# DSP_ICFG register map
Vendor: Texas Instruments
Peripheral module from a debugger description file (folder awr2544).
Registers are 32-bit, access not given, no defined reset value unless marked. A register's access mark holds for its fields unless they carry their own. Offsets are as the file gives them; lines under a group give offsets from that group; [hi:lo] are bit positions; {n}, {i} and the like mark numbered series; 'fields as' and 'values as' point back to an identical list; <NAME> marks a mode.

## DSP_ICFG
0x00 EVTFLAG0_{i} ro (i=0..3) — Event flags
  [31:0] EF
{0x4+4i} EVTFLAG1_{i} ro (i=0..3) — Event flags
  [31:0] EF
{0x8+4i} EVTFLAG2_{i} ro (i=0..3) — Event flags
  [31:0] EF
{0xC+4i} EVTFLAG3_{i} ro (i=0..3) — Event flags
  [31:0] EF
{0x20+4i} EVTSET{i}_0 wo (i=0..3) — Event set command register
  [31:0] ES — Event set command
{0x24+4i} EVTSET{i}_1 wo (i=0..3) — Event set command register
  [31:0] ES — Event set command
{0x28+4i} EVTSET{i}_2 wo (i=0..3) — Event set command register
  [31:0] ES — Event set command
{0x2C+4i} EVTSET{i}_3 wo (i=0..3) — Event set command register
  [31:0] ES — Event set command
{0x40+4i} EVTCLR{i}_0 wo (i=0..3) — Event clear command register
  [31:0] EC — Event clear command
{0x44+4i} EVTCLR{i}_1 wo (i=0..3) — Event clear command register
  [31:0] EC — Event clear command
{0x48+4i} EVTCLR{i}_2 wo (i=0..3) — Event clear command register
  [31:0] EC — Event clear command
{0x4C+4i} EVTCLR{i}_3 wo (i=0..3) — Event clear command register
  [31:0] EC — Event clear command
{0x80+4i} EVTMASK{i}_0 rw (i=0..3) — Event mask register
  [31:0] EM — Event mask
{0x84+4i} EVTMASK{i}_1 rw (i=0..3) — Event mask register
  [31:0] EM — Event mask
{0x88+4i} EVTMASK{i}_2 rw (i=0..3) — Event mask register
  [31:0] EM — Event mask
{0x8C+4i} EVTMASK{i}_3 rw (i=0..3) — Event mask register
  [31:0] EM — Event mask
{0xA0+4i} MEVTFLAG{i}_0 ro (i=0..3) — Masked event flags
  [31:0] MEVTFLAG
{0xA4+4i} MEVTFLAG{i}_1 ro (i=0..3) — Masked event flags
  [31:0] MEVTFLAG
{0xA8+4i} MEVTFLAG{i}_2 ro (i=0..3) — Masked event flags
  [31:0] MEVTFLAG
{0xAC+4i} MEVTFLAG{i}_3 ro (i=0..3) — Masked event flags
  [31:0] MEVTFLAG
{0xC0+4i} EXPMASK{i}_0 rw (i=0..3) — Exception mask register
  [31:0] XM — Exception mask
{0xC4+4i} EXPMASK{i}_1 rw (i=0..3) — Exception mask register
  [31:0] XM — Exception mask
{0xC8+4i} EXPMASK{i}_2 rw (i=0..3) — Exception mask register
  [31:0] XM — Exception mask
{0xCC+4i} EXPMASK{i}_3 rw (i=0..3) — Exception mask register
  [31:0] XM — Exception mask
{0xE0+4i} MEXPFLAG{i}_0 ro (i=0..3) — Masked exception flags
  [31:0] MEXPFLAG
{0xE4+4i} MEXPFLAG{i}_1 ro (i=0..3) — Masked exception flags
  [31:0] MEXPFLAG
{0xE8+4i} MEXPFLAG{i}_2 ro (i=0..3) — Masked exception flags
  [31:0] MEXPFLAG
{0xEC+4i} MEXPFLAG{i}_3 ro (i=0..3) — Masked exception flags
  [31:0] MEXPFLAG
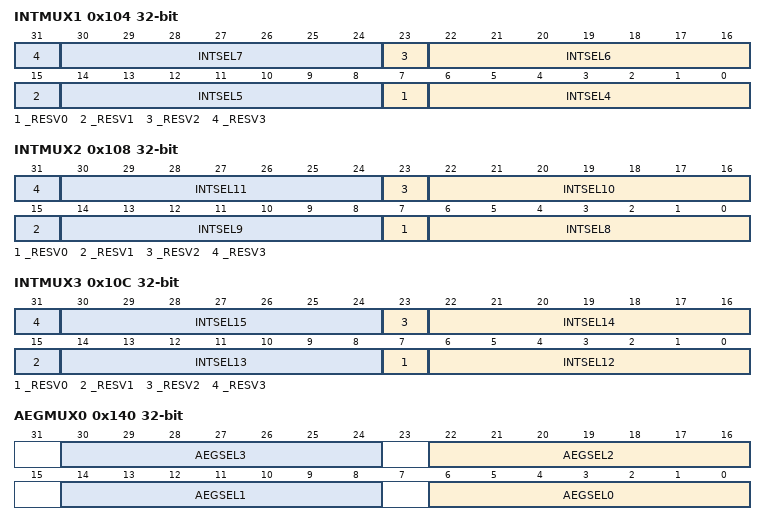
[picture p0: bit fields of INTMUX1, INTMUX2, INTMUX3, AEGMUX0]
0x104 INTMUX1 — Interrupt Mux Register
  [8n+7] _RESV{n} (n=0..3) — Always read as 0. Writes have no affect.
  [8n-26:8n-32] INTSEL{n} rw (n=4..7) — Interrupt selector {n}
0x108 INTMUX2 — Interrupt Mux Register
  [8n+7] _RESV{n} (n=0..3) — Always read as 0. Writes have no affect.
  [8n-58:8n-64] INTSEL{n} rw (n=8..11) — Interrupt selector {n}
0x10C INTMUX3 — Interrupt Mux Register
  [8n+7] _RESV{n} (n=0..3) — Always read as 0. Writes have no affect.
  [8n-90:8n-96] INTSEL{n} rw (n=12..15) — Interrupt selector {n}
0x140 AEGMUX0 rw — AEG Event Mux Register
  [8n+6:8n] AEGSEL{n} (n=0..3) — AEG event selector {n}
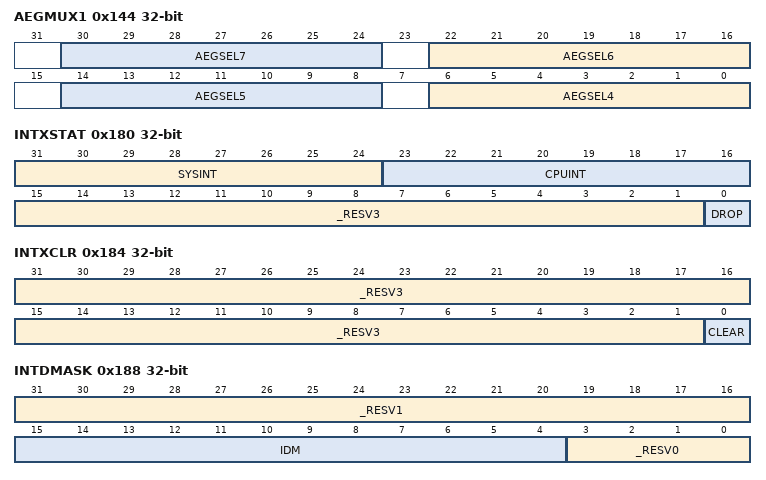
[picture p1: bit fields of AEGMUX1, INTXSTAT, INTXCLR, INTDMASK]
0x144 AEGMUX1 rw — AEG Event Mux Register
  [8n-26:8n-32] AEGSEL{n} (n=4..7) — AEG event selector {n}
0x180 INTXSTAT — Interrupt Exception Status Register
  [31:24] SYSINT ro — System event number
  [23:16] CPUINT ro — CPU interrupt number
  [15:1] _RESV3 — Always read as 0. Writes have no affect.
  [0] DROP ro — Dropped event flag
0x184 INTXCLR — Interrupt Exception Clear Register
  [31:1] _RESV3 — Always read as 0. Writes have no affect.
  [0] CLEAR wo — Clear interrupt exception status
0x188 INTDMASK — Dropped Interrupt Mask Register
  [31:16] _RESV1 — Always read as 0. Writes have no affect.
  [15:4] IDM rw — Interrupt drop mask
  [3:0] _RESV0 — Always read as 0. Writes have no affect.
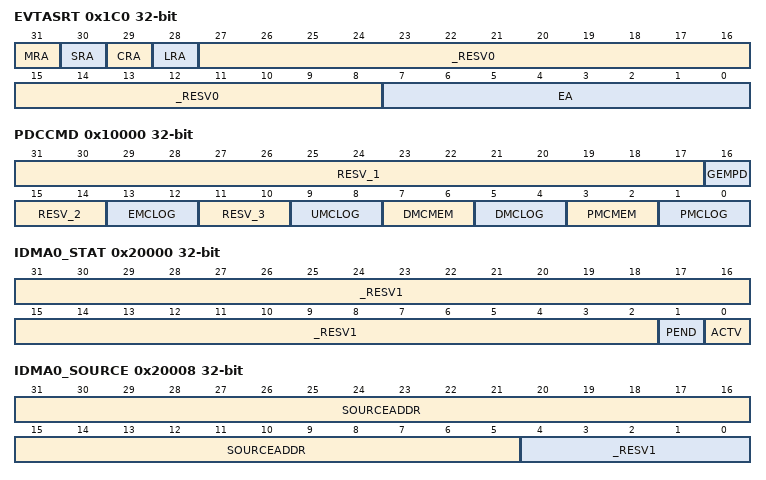
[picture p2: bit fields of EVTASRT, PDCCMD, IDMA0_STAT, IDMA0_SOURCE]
0x1C0 EVTASRT — Event Assert Register
  [31] MRA wo — Maximal Reset Request Assert
  [30] SRA wo — System Reset Request Assert
  [29] CRA wo — Chip Reset Request Assert
  [28] LRA wo — Local Reset Request Assert
  [27:8] _RESV0 — Always read as 0. Writes have no affect.
  [7:0] EA wo — Event Assert
0x10000 PDCCMD
  [31:17] RESV_1 — Always read as 0. Writes have no affect.
  [16] GEMPD rw — Enable power-down during IDLE
  [15:14] RESV_2 — Always read as 0. Writes have no affect.
  [13:12] EMCLOG rw — EMC SRAM Sleep Mode
  [11:10] RESV_3 — Always read as 0. Writes have no affect.
  [9:8] UMCLOG rw — UMC SRAM Sleep Mode
  [7:6] DMCMEM rw — DMC Logic Clock Gating
  [5:4] DMCLOG rw — DMC SRAM Sleep Mode
  [3:2] PMCMEM rw — PMC Logic Clock Gating
  [1:0] PMCLOG rw — PMC SRAM Sleep Mode
0x12000 MM_REVID rw
0x20000 IDMA0_STAT — IDMA Channel 0 Status
  [31:2] _RESV1 — Always read as 0. Writes have no affect.
  [1] PEND ro — Command pending
  [0] ACTV ro — Command active
0x20004 IDMA0_MASK rw — IDMA Channel 0 Register Mask
0x20008 IDMA0_SOURCE — IDMA Channel 0 Source Address
  [31:5] SOURCEADDR rw — Source address
  [4:0] _RESV1 — Always read as 0. Writes have no affect.
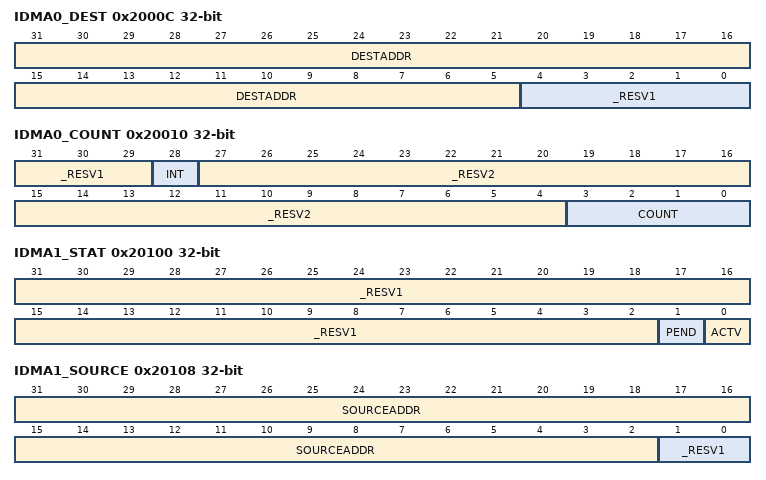
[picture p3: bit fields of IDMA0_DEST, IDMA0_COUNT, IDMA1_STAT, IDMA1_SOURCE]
0x2000C IDMA0_DEST — IDMA Channel 0 Destination Address
  [31:5] DESTADDR rw — Destination address
  [4:0] _RESV1 — Always read as 0. Writes have no affect.
0x20010 IDMA0_COUNT — IDMA Channel 0 Count
  [31:29] _RESV1 — Always read as 0. Writes have no affect.
  [28] INT rw — Interrupt enable
  [27:4] _RESV2 — Always read as 0. Writes have no affect.
  [3:0] COUNT rw — Transfer frame count
0x20100 IDMA1_STAT
  fields as IDMA0_STAT
0x20108 IDMA1_SOURCE
  [31:2] SOURCEADDR rw — Source address
  [1:0] _RESV1 — Always read as 0. Writes have no affect.
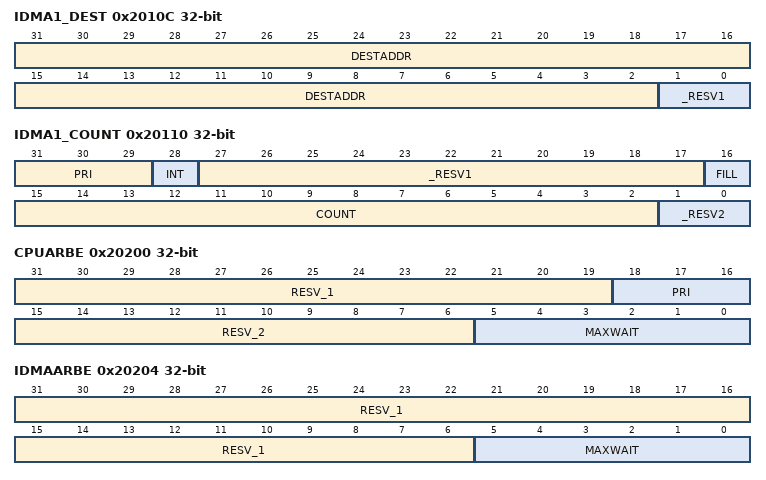
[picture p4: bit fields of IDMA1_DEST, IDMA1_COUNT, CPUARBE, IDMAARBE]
0x2010C IDMA1_DEST
  [31:2] DESTADDR rw — Destination address
  [1:0] _RESV1 — Always read as 0. Writes have no affect.
0x20110 IDMA1_COUNT
  [31:29] PRI rw — Priority
  [28] INT rw — Interrupt enable
  [27:17] _RESV1 — Always read as 0. Writes have no affect.
  [16] FILL rw — Fill/Copy Mode Select
  [15:2] COUNT rw — Transfer word count
  [1:0] _RESV2 — Always read as 0. Writes have no affect.
0x20200 CPUARBE
  [31:19] RESV_1 — Always read as 0. Writes have no affect.
  [18:16] PRI rw — Priority
  [15:6] RESV_2 — Always read as 0. Writes have no affect.
  [5:0] MAXWAIT rw — Max wait count
0x20204 IDMAARBE
  [31:6] RESV_1 — Always read as 0. Writes have no affect.
  [5:0] MAXWAIT rw — Max wait count
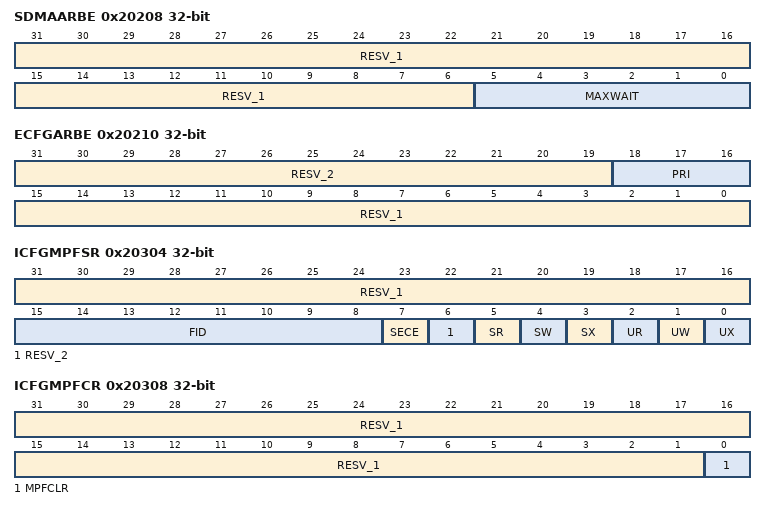
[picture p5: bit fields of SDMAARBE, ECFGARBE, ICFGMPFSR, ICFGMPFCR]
0x20208 SDMAARBE
  fields as IDMAARBE
0x20210 ECFGARBE
  [31:19] RESV_2 — Always read as 0. Writes have no affect.
  [18:16] PRI rw — Priority
  [15:0] RESV_1 — Always read as 0. Writes have no affect.
0x20300 ICFGMPFAR ro
  [31:0] ADDR
0x20304 ICFGMPFSR
  [31:16] RESV_1 — Always read as 0. Writes have no affect.
  [15:8] FID ro — PrivID of faulting requestor
  [7] SECE ro — Security Error
  [6] RESV_2 — Always read as 0. Writes have no affect.
  [5] SR ro — Fault due to Supervisor Read
  [4] SW ro — Fault due to Supervisor Write
  [3] SX ro — Fault due to Supervisor Execute
  [2] UR ro — Fault due to User Read
  [1] UW ro — Fault due to User Write
  [0] UX ro — Fault due to User Execute
0x20308 ICFGMPFCR
  [31:1] RESV_1 — Always read as 0. Writes have no affect.
  [0] MPFCLR wo
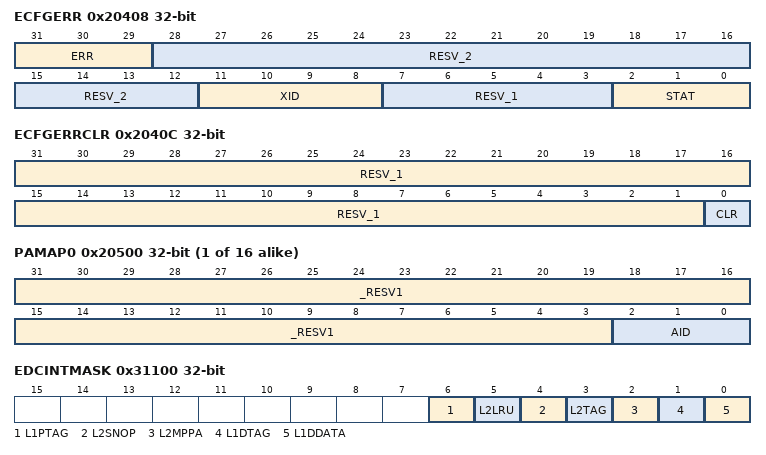
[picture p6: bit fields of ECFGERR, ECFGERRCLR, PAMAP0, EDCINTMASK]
0x20408 ECFGERR
  [31:29] ERR ro — Error
  [28:12] RESV_2 — Always read as 0. Writes have no affect.
  [11:8] XID ro
  [7:3] RESV_1 — Always read as 0. Writes have no affect.
  [2:0] STAT ro — Status
0x2040C ECFGERRCLR
  [31:1] RESV_1 — Always read as 0. Writes have no affect.
  [0] CLR ro — Error clear
{0x20500+4i} PAMAP{i} (i=0..15) — PAMAP register
  [31:3] _RESV1 — Always read as 0. Writes have no affect.
  [2:0] AID rw
0x31100 EDCINTMASK — This read write registers contains the masks for the exceptions generated by each of the EDC error detection units added in this change. Also contained in this register are the bit fields indicating which module has issued an exception. Reads of this register do not affect the mask bits but do clear the exception bits.
  [6] L1PTAG — L1PTAG Exception Enable: 1 enables the propagation of the exceptions generated from the error detector. Write 0 to disable exceptions.
  [5] L2LRU — L2LRU Exception Enable: 1 enables the propagation of the exceptions generated from the error detector. Write 0 to disable exceptions.
  [4] L2SNOP — L2SNOP Exception Enable: 1 enables the propagation of the exceptions generated from the error detector. Write 0 to disable exceptions.
  [3] L2TAG — L2TAG Exception Enable: 1 enables the propagation of the exceptions generated from the error detector. Write 0 to disable exceptions.
  [2] L2MPPA — L2DMPPA Exception Enable: 1 enables the propagation of the exceptions generated from the error detector. Write 0 to disable exceptions.
  [1] L1DTAG — L1DTAG Exception Enable: 1 enables the propagation of the exceptions generated from the error detector. Write 0 to disable exceptions.
  [0] L1DDATA — L1DDATA Exception Enable: 1 enables the propagation of the exceptions generated from the error detector. Write 0 to disable exceptions.
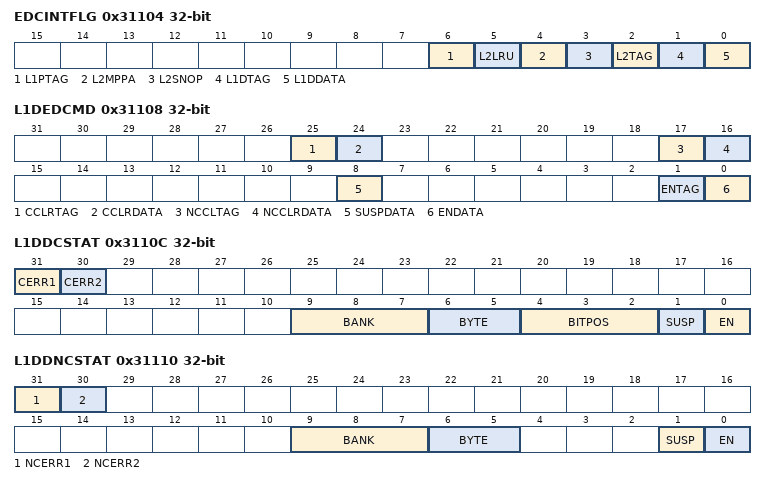
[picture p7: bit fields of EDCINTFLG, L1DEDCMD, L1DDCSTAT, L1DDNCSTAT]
0x31104 EDCINTFLG — This register loads the interrupt flags upon issue by the EDC detection module. These flags are loaded independently of any other flags. Upon a read operation all flags are cleared.
  [6] L1PTAG — L1P TAG Exception: 1 indicates that an exception has been issued from this error detector. Read of register clears bit.
  [5] L2LRU — L2 LRU Exception: 1 indicates that an exception has been issued from this error detector. Read of register clears bit.
  [4] L2MPPA — L2 MPPA Exception: 1 indicates that an exception has been issued from this error detector. Read of register clears bit.
  [3] L2SNOP — L2 SNOP Exception: 1 indicates that an exception has been issued from this error detector. Read of register clears bit.
  [2] L2TAG — L2TAG Exception: 1 indicates that an exception has been issued from this error detector. Read of register clears bit.
  [1] L1DTAG — L1DTAG Exception: 1 indicates that an exception has been issued from this error detector. Read of register clears bit.
  [0] L1DDATA — L1DDATA Exception: 1 indicates that an exception has been issued from this error detector. Read of register clears bit.
0x31108 L1DEDCMD — This write only register provides control for enabling and disabling the ECC logic ofr the DMC. This register controls the parameters which are accumulated for the Data and Tag RAMs in the DMC. Enabling the ECC allows the counting of recoverable and non-recoverable errors as well as registering the requestor and the address and cache states for any ECC errors which are reported.
  [25] CCLRTAG rw — Correctable Error Clear: Writing 1 clears the correctable error count in the DMCEDPECNT register This is a one-shot register, and is cleared immediately.
  [24] CCLRDATA rw — Non-Correctable Error Clear: Writeing 1 clears the noncorrectable error count in the DMCEDPECNT register. This is a one-shot register and is cleared immediately.
  [17] NCCLTAG rw — Correctable Error Clear: Writing 1 clears the correctable error count in the DMCEDPECNT register This is a one-shot register, and is cleared immediately.
  [16] NCCLRDATA rw — Non-Correctable Error Clear: Writeing 1 clears the noncorrectable error count in the DMCEDPECNT register. This is a one-shot register and is cleared immediately.
  [8] SUSPDATA rw — Suspend TAG: Write 1 to prevent hamming codes from being written into memory but allows data to be written.
  [1] ENTAG rw — Enable Data: Initialized to the active state (1), to disable EDC on Data write 0
  [0] ENDATA rw — Enable TAG: Initialized to the active state (1), to disable EDC on TAG write 0.
0x3110C L1DDCSTAT — This read only regsister contains the current error data for Correctable ECC errors. The register provides information on whether the error was correctable or non-correctable, the requestor, and what position the error was located. . The error information is written upon the occurrence of the first ECC error encountered. CERR1 is set, and the values are retained. If any additional ECC errors occur, this is indicated by setting CERR2.
  [31] CERR1 — Correctable Error 1: Indicates that one correctable error has occurred and that they BANK, BYTE and BITPOS values are valid. Cleared upon writing a 1 to L1DEDCMD.CCLRDATA
  [30] CERR2 — Correctable Error 2: Indicates that a subsequent correctable error has occurred ,BANK, BYTE and BITPOS values are valid but apply to the error reported in CERR1. Cleared upon writing a 1 to L1DEDCMD.CCLRDATA
  [9:7] BANK — BANK Number: This value indicates the bank number of the error indicated when CERR1 is 1. This value is the lowest numbered bank if multiple banks error simultaneously. This value is set upon the first error occurring and is cleared by writing a 1 to L1DEDCMD.CCLRDATA.
  [6:5] BYTE — Byte Number: This value indicates the byte number ot the error indicated when CERR1 is 1. This value is the lowest numbered byte if multiple bytes error simultaneously in the same bank.This value is set upon the first error occurring and is cleared by writing a 1 to L1DEDCMD.CCLRDATA.
  [4:2] BITPOS — Bit Position: This value indicates the bit position of the error indicated when CERR1 is 1. This value is the specific single error bits from the byte indicated by BYTE and the bank indicated by BANK. This value is set upon the first error occurring and is cleared by writing a 1 to L1DEDCMD.CCLRDATA.
  [1] SUSP — Suspend: EDC logic is in suspend mode, this value is representative of the state of the last write to L1DEDCMD.SUSPDATA.
  [0] EN — EDC Enable: Indicates EDC logic is enabled, this value is representative of the state of the last write to L1DEDCMD.ENDATA.
0x31110 L1DDNCSTAT — This read only register contains the current error data for Correctable ECC errors. The register provides information on whether the error was correctable or non-correctable, the requestor, and what position the error was located. This register is similar to Error! Not a valid bookmark self-reference. with the exception of the bit position register fields, with two bit errors it is not possible to provide the locations. . The error information is written upon the occurrence of the first ECC error encountered. CERR1 is set, and the values are retained. If any additional ECC errors occur, this is indicated by setting CERR2. Note: Non-correctable errors do not mean two bits in the 256 bit data word, but two bits+ of error in a single byte. The EDC is capable of correcting up to 8 bits in a single word if there are only single bit errors in each byte.
  [31] NCERR1 — Non-Correctable Error 1: Indicates that one correctable error has occurred and that they BANK, BYTE and BITPOS values are valid. Cleared upon writing a 1 to L1DEDCMD.NCCLRDATA
  [30] NCERR2 — Non-Correctable Error 2: Indicates that a subsequent correctable error has occurred ,BANK, BYTE and BITPOS values are valid but apply to the error reported in CERR1. Cleared upon writing a 1 to L1DEDCMD.NCCLRDATA
  [9:7] BANK — BANK Number: This value indicates the bank number of the error indicated when NCERR1 is 1. This value is the lowest numbered bank if multiple banks error simultaneously. This value is set upon the first error occurring and is cleared by writing a 1 to L1DEDCMD.NCCLRDATA.
  [6:5] BYTE — Byte Number: This value indicates the byte number ot the error indicated when NCERR1 is 1. This value is the lowest numbered byte if multiple bytes error simultaneously in the same bank.This value is set upon the first error occurring and is cleared by writing a 1 to L1DEDCMD.NCCLRDATA.
  [1] SUSP — Suspend: EDC logic is in suspend mode, this value is representative of the state of the last write to L1DEDCMD.SUSPDATA
  [0] EN — EDC Enable: Indicates EDC logic is enabled, this value is representative of the state of the last write to L1DEDCMD.ENDATA.
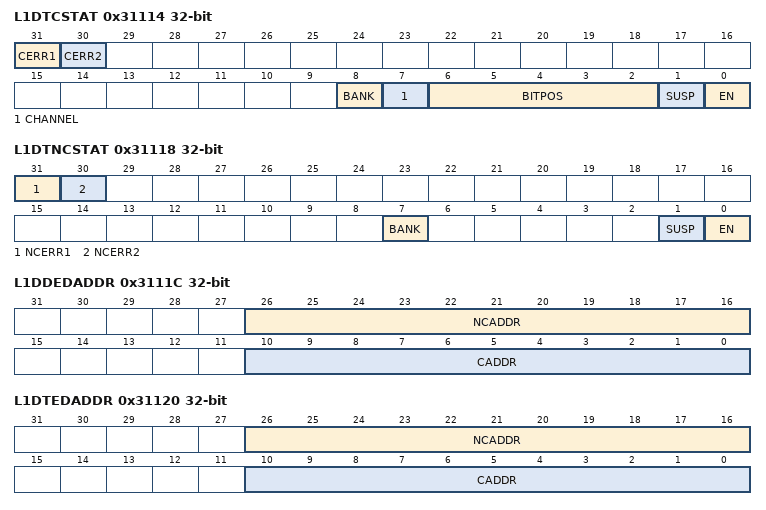
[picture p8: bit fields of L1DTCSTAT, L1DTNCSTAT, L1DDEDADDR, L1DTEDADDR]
0x31114 L1DTCSTAT — This read only regsister contains the current error data for Correctable ECC errors. The register provides information on whether the error was correctable or non-correctable, the requestor, and what position the error was located. The error information is written upon the occurrence of the first ECC error encountered. CERR1 is set, and the values are retained. If any additional ECC errors occur, this is indicated by setting CERR2.
  [31] CERR1 — Correctable Error 1: Indicates that one correctable error has occurred and that they BANK and BITPOS values are valid. Cleared upon writing a 1 to L1DEDCMD.CCLRDTAG
  [30] CERR2 — Correctable Error 2: Indicates that a subsequent correctable error has occurred ,BANK and BITPOS values are valid but apply to the error reported in CERR1. Cleared upon writing a 1 to L1DEDCMD.CCLRTAG
  [8] BANK ro — Bank: Value indicates which bank the correctable error occurred in.
  [7] CHANNEL — Channel: Access to the banks of the L1D TAG memory are split into channels: 1 = [53:43],[31:16] 2 = [42:32],[15:0] Bit Position is an index in the respective channels, this will yield the error bit position.
  [6:2] BITPOS ro — Bit Position: This value indicates the bit position of the error indicated when CERR1 is 1. This value is the specific single error bits from the byte indicated by BYTE and the bank indicated by BANK. This value is set upon the first error occurring Cleared upon writing a 1 to L1DEDCMD.CCLRTAG
  [1] SUSP — Suspend: EDC logic is in suspend mode, this value is representative of the state of the last write to L1DEDCMD.SUSPDATA
  [0] EN — EDC Enable: Indicates EDC logic is enabled, this value is representative of the state of the last write to L1DEDCMD.ENDATA.
0x31118 L1DTNCSTAT — L1D Error Detect TAG Non-Correctable Status Register
  [31] NCERR1 — Non-Correctable Error 1: Indicates that one correctable error has occurred and that they BANK, BYTE and BITPOS values are valid. Cleared upon writing a 1 to L1DEDCMD.NCCLRTAG
  [30] NCERR2 — Non-Correctable Error 2: Indicates that a subsequent correctable error has occurred ,BANK, BYTE and BITPOS values are valid but apply to the error reported in CERR1. Cleared upon writing a 1 to L1DEDCMD.NCCLRTAG
  [7] BANK — BANK Number: This value indicates the bank number of the error indicated when NCERR1 is 1. This value is the lowest numbered bank if multiple banks error simultaneously. This value is set upon the first error occurring and is cleared by writing a 1 to L1DEDCMD.NCCLRDATA.
  [1] SUSP — Suspend: EDC logic is in suspend mode, this value is representative of the state of the last write to L1DEDCMD.SUSPDATA
  [0] EN — EDC Enable: Indicates EDC logic is enabled, this value is representative of the state of the last write to L1DEDCMD.ENDATA.
0x3111C L1DDEDADDR — The L1D Correctable Error Detection Address Register pair contain the additional information on correctable errors reported in the STATUS registers. The addresses for both correctable and noncorrectable errors are held in this register. The value contained in the addresss field is the lower 16 bits of the word boundary of the memory access. If the access is to 0x00F00020, the address field will read 0x0020, if the access is to 0x00F07FE0, the address field will read 0x7FE0.
  [26:16] NCADDR — Non-Correctable Address: The value in this field is qualified by L1DEDDNCSTATE.NCERR1, when that field is written to a 1, the address of the noncorrectable error is written to this register field. . Cleared upon writing a 1 to L1DEDCMD.NCCLRDATA
  [10:0] CADDR — Correctable Address: The value in this field is qualified by L1DEDDNCSTATE.CERR1, when that field is written to a 1, the address of the non-correctable error is written to this register field. . Cleared upon writing a 1 to L1DEDCMD.NCCLRDATA
0x31120 L1DTEDADDR — The L1D Correctable Error Detection Address Register pair contain the additional information on correctable errors reported in the STATUS registers. The address for both correctable and noncorrectable errors are held in this register. The value of the address is the index (or address on the RAM) of the RAM module.
  fields as L1DDEDADDR
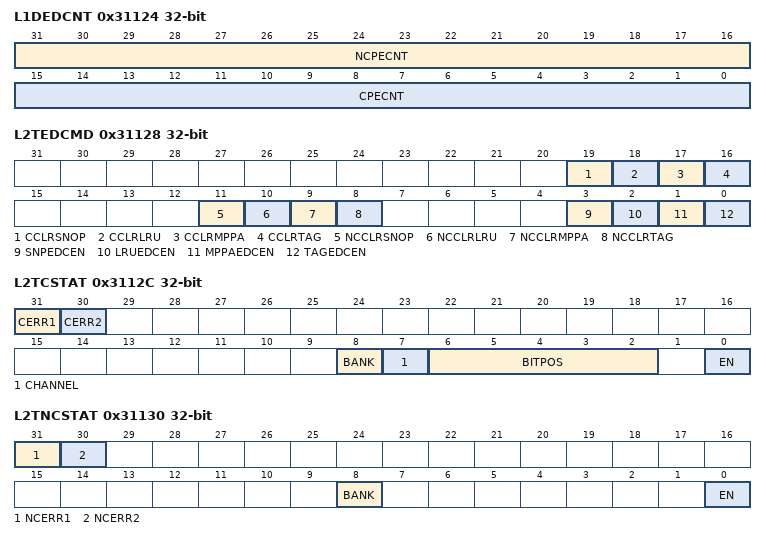
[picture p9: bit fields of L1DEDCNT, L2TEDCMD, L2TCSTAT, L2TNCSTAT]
0x31124 L1DEDCNT ro — The L1D TAG Error Detection Error Count Register.stores the error counts for correctable and noncorrectable errors which occur in the L1D Cache Memories, these counts are accumulated regardless of the exception mapping in the L1DEDCMD (0x0182_1108) interrupt enable bits. The counters capture the total number of correctable and non-correctable errors from both the DATA and TAG memories.
  [31:16] NCPECNT — Non-correctable EDC error count. Shows the number of non-correctable errors which have occurred in the DMC memories since last reset. This counter is cleared by writing a zero value to the counter.
  [15:0] CPECNT — Correctable EDC error count: Shows the number of correctable errors which have occurred in the DMC memories since last reset. This counter is cleared by writing a zero value to the counter.
0x31128 L2TEDCMD — This write only register provides control for enabling and disabling the ECC logic ofr the UMC. This register controls the parameters which are accumulated for the Data and Tag RAMs in the DMC. Enabling the ECC allows the counting of recoverable and non-recoverable errors as well as registering the requestor and the address and cache states for any ECC errors which are reported.
  [19] CCLRSNOP wo — Correctable Error Clear, SNOP: writing 1 to this register cause the corresponding counter to be cleared. The value written to this register is a one shot event.
  [18] CCLRLRU wo — Correctable Error Clear, LRU: writing 1 to this register cause the corresponding counter to be cleared. The value written to this register is a one shot event.
  [17] CCLRMPPA wo — Correctable Error Clear, MPPA: writing 1 to this register cause the corresponding counter to be cleared. The value written to this register is a one shot event.
  [16] CCLRTAG wo — Correctable Error Clear, TAG: writing 1 to this register cause the corresponding counter to be cleared. The value written to this register is a one shot event.
  [11] NCCLRSNOP wo — Non- Correctable Error Clear, SNOP: writing 1 to this register cause the corresponding counter to be cleared. The value written to this register is a one shot event.
  [10] NCCLRLRU wo — Non- Correctable Error Clear, LRU: writing 1 to this register cause the corresponding counter to be cleared. The value written to this register is a one shot event.
  [9] NCCLRMPPA wo — Non- Correctable Error Clear, MPPA: writing 1 to this register cause the corresponding counter to be cleared. The value written to this register is a one shot event.
  [8] NCCLRTAG wo — Non- Correctable Error Clear, TAG: writing 1 to this register cause the corresponding counter to be cleared. The value written to this register is a one shot event.
  [3] SNPEDCEN wo — Enable EDC: writing a 1 to this register enables EDC on the SNOOP Memory
  [2] LRUEDCEN wo — Enable EDC: writing a 1 to this register enables EDC on the LRU Memory
  [1] MPPAEDCEN wo — Enable EDC: writing a 1 to this register enables EDC on the MPPA Memory
  [0] TAGEDCEN wo — Enable EDC: writing a 1 to this register enables the EDC modules for this memory. This bit is persistent and must be actively written to 0 to disable the EDC modules.
0x3112C L2TCSTAT — This read only regsister contains the current error data for Correctable ECC errors. The register provides information on whether the error was correctable or non-correctable, the requestor, and what position the error was located.
  [31] CERR1 ro — Correctable Error 1: Indicates that one correctable error has occurred and that they BANK and BITPOS values are valid. Cleared upon writing a 1 to L2EDCMD.CCLRDTAG
  [30] CERR2 ro — Correctable Error 2: Indicates that a subsequent correctable error has occurred ,BANK and BITPOS values are valid but apply to the error reported in CERR1. Cleared upon writing a 1 to L2EDCMD.CCLRTAG
  [8] BANK ro — Bank: indicates which of the two banks (0 = BANK0, 1 = BANK1) contains the correctable error. Cleared upon writing a 1 to L2EDCMD.CCLRTAG
  [7] CHANNEL ro — Channel: Access to a bank are split, therefore an indication of channel 1 = [41:21] 2 = [20:0] Bit Position is qualified from these as displacements within the channel.
  [6:2] BITPOS ro — Bit Position: This value indicates the bit position of the error indicated when CERR1 is 1. This value is the specific single error bits from the byte indicated by BYTE and the bank indicated by BANK. This value is set upon the first error occurring Cleared upon writing a 1 to L2EDCMD.CCLRTA
  [0] EN ro — EDC Enable: Indicates EDC logic is enabled, this value is representative of the state of the last write to L1DEDCMD.ENDATA.
0x31130 L2TNCSTAT — This read only register contains the current error data for Correctable ECC errors. The register provides information on whether the error was correctable or non-correctable, the requestor, and what position the error was located.
  [31] NCERR1 ro — Non-Correctable Error 1: Indicates that one correctable error has occurred and that they BANK, BYTE and BITPOS values are valid. Cleared upon writing a 1 to L1DEDCMD.NCCLRTAG
  [30] NCERR2 ro — Non-Correctable Error 2: Indicates that a subsequent correctable error has occurred ,BANK, BYTE and BITPOS values are valid but apply to the error reported in CERR1. Cleared upon writing a 1 to L1DEDCMD.NCCLRTAG
  [8] BANK ro — Bank: indicates which of the two banks (0 = BANK0, 1 = BANK1) contains the correctable error. Cleared upon writing a 1 to L2EDCMD.CCLRTAG
  [0] EN ro — EDC Enable: Indicates EDC logic is enabled, this value is representative of the state of the last write to L1DEDCMD.ENDATA.
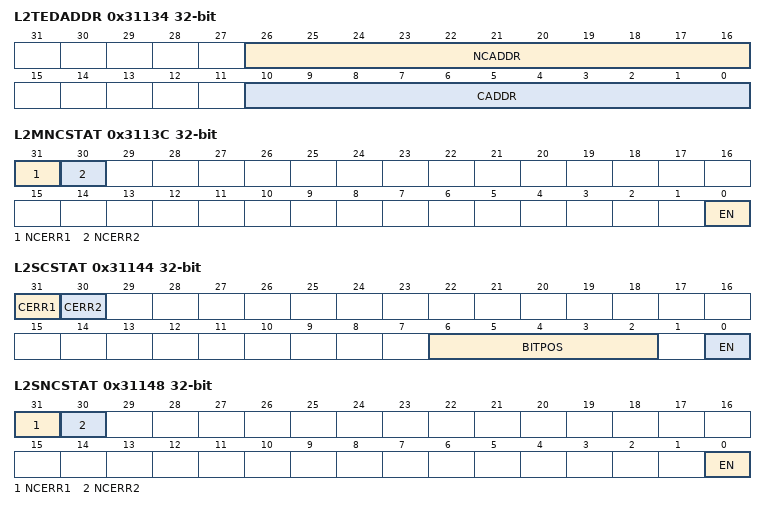
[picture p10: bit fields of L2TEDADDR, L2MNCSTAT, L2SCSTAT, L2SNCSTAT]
0x31134 L2TEDADDR — The L2Correctable Error Detection Address Register pair contain the additional information on correctable errors reported in1.3.1.12. With both exceptions activated, the TAG exception will take priority on simultaneous exceptions. The addres in these fields is the displacement into the memory as presented to the address port of the SRAM.
  [26:16] NCADDR ro — Non-Correctable Address: The value in this field is qualified by L2EDDNCSTATE.NCERR1, when that field is written to a 1, the address of the noncorrectable error is written to this register field. . Cleared upon writing a 1 to L2EDCMD.NCCLRDATA
  [10:0] CADDR ro — Correctable Address: The value in this field is qualified by L2EDDNCSTATE.CERR1, when that field is written to a 1, the address of the non-correctable error is written to this register field. . Cleared upon writing a 1 to L2EDCMD.NCCLRDATA
0x31138 L2MCSTAT — This register is non-functional as the memory is protected by parity alone and thus is non-correctable.
0x3113C L2MNCSTAT — This read only register contains the current error data for Correctable ECC errors. The register provides information on whether the error was correctable or non-correctable, the requestor, and what position the error was located.
  [31] NCERR1 ro — Non-Correctable Error 1: Indicates that one correctable error has occurred and that they BANK, BYTE and BITPOS values are valid. Cleared upon writing a 1 to L2EDCMD.NCCLRMPPA
  [30] NCERR2 ro — Non-Correctable Error 2: Indicates that a subsequent correctable error has occurred ,BANK, BYTE and BITPOS values are valid but apply to the error reported in CERR1. Cleared upon writing a 1 to L2EDCMD.NCCLRMPPA
  [0] EN ro — EDC Enable: Indicates EDC logic is enabled, this value is representative of the state of the last write to L1DEDCMD.ENEDC
0x31140 L2MEDADDR — The L2Correctable Error Detection Address Register pair contain the additional information on correctable errors reported in1.3.1.12. With both exceptions activated, the TAG exception will take priority on simultaneous exceptions.
  [26:16] NCADDR ro — Non-Correctable Address: The value in this field is qualified by L2EDSNCSTATE.NCERR1, when that field is written to a 1, the address of the non-correctable error is written to this register field. . Cleared upon writing a 1 to L2EDCMD.NCCLRMPPA
0x31144 L2SCSTAT — This read only regsister contains the current error data for Correctable ECC errors. The register provides information on whether the error was correctable or non-correctable, the requestor, and what position the error was located.
  [31] CERR1 ro — Correctable Error 1: Indicates that one correctable error has occurred and that they BANK and BITPOS values are valid. Cleared upon writing a 1 to L2EDCMD.CCLRDSNOP
  [30] CERR2 ro — Correctable Error 2: Indicates that a subsequent correctable error has occurred ,BANK and BITPOS values are valid but apply to the error reported in CERR1. Cleared upon writing a 1 to L2EDCMD.CCLRSNOP
  [6:2] BITPOS ro — Bit Position: This value indicates the bit position of the error indicated when CERR1 is 1. This value is the specific single error bits from the byte indicated by BYTE and the bank indicated by BANK. This value is set upon the first error occurring Cleared upon writing a 1 to L2EDCMD.CCLRSNOP
  [0] EN ro — EDC Enable: Indicates EDC logic is enabled, this value is representative of the state of the last write to L2EDCMD.ENEDC
0x31148 L2SNCSTAT — This read only register contains the current error data for Correctable ECC errors. The register provides information on whether the error was correctable or non-correctable, the requestor, and what position the error was located.
  [31] NCERR1 ro — Non-Correctable Error 1: Indicates that one correctable error has occurred and that they BANK, BYTE and BITPOS values are valid. Cleared upon writing a 1 to L2EDCMD.NCCLRSNOP
  [30] NCERR2 ro — Non-Correctable Error 2: Indicates that a subsequent correctable error has occurred ,BANK, BYTE and BITPOS values are valid but apply to the error reported in CERR1. Cleared upon writing a 1 to L2EDCMD.NCCLRSNOP
  [0] EN ro — EDC Enable: Indicates EDC logic is enabled, this value is representative of the state of the last write to L2EDCMD.ENEDC
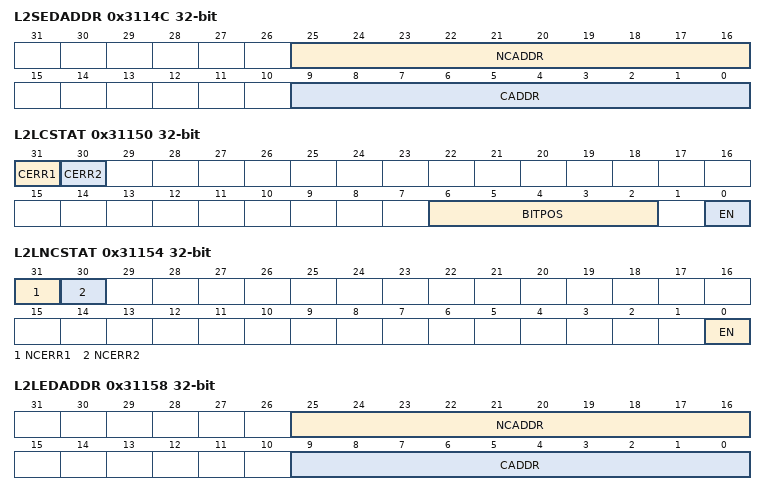
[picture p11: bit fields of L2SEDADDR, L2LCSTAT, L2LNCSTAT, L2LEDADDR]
0x3114C L2SEDADDR — The L2Correctable Error Detection Address Register pair contain the additional information on correctable errors reported in1.3.1.12. With both exceptions activated, the TAG exception will take priority on simultaneous exceptions.
  [25:16] NCADDR ro — Non-Correctable Address: The value in this field is qualified by L2EDDNCSTATE.NCERR1, when that field is written to a 1, the address of the noncorrectable error is written to this register field. . Cleared upon writing a 1 to L2EDCMD.NCCLRSNOP
  [9:0] CADDR ro — Correctable Address: The value in this field is qualified by L2EDDNCSTATE.CERR1, when that field is written to a 1, the address of the non-correctable error is written to this register field. . Cleared upon writing a 1 to L2EDCMD.NCCLRSNOP
0x31150 L2LCSTAT — This read only regsister contains the current error data for Correctable ECC errors. The register provides information on whether the error was correctable or non-correctable, the requestor, and what position the error was located.
  [31] CERR1 ro — Correctable Error 1: Indicates that one correctable error has occurred and that they BANK and BITPOS values are valid. Cleared upon writing a 1 to L2EDCMD.CCLRDLRU
  [30] CERR2 ro — Correctable Error 2: Indicates that a subsequent correctable error has occurred ,BANK and BITPOS values are valid but apply to the error reported in CERR1. Cleared upon writing a 1 to L2EDCMD.CCLRLRU
  [6:2] BITPOS ro — Bit Position: This value indicates the bit position of the error indicated when CERR1 is 1. This value is the specific single error bits from the byte indicated by BYTE and the bank indicated by BANK. This value is set upon the first error occurring Cleared upon writing a 1 to L2EDCMD.CCLRLRU
  [0] EN ro — EDC Enable: Indicates EDC logic is enabled, this value is representative of the state of the last write to L2EDCMD.ENEDC
0x31154 L2LNCSTAT
  [31] NCERR1 — Non-Correctable Error 1: Indicates that one correctable error has occurred and that they BANK, BYTE and BITPOS values are valid. Cleared upon writing a 1 to L2EDCMD.NCCLR:LRU
  [30] NCERR2 — Non-Correctable Error 2: Indicates that a subsequent correctable error has occurred ,BANK, BYTE and BITPOS values are valid but apply to the error reported in CERR1. Cleared upon writing a 1 to L2EDCMD.NCCLRLRU
  [0] EN — EDC Enable: Indicates EDC logic is enabled, this value is representative of the state of the last write to L2EDCMD.ENEDC
0x31158 L2LEDADDR ro — The L2Correctable Error Detection Address Register pair contain the additional information on correctable errors reported in1.3.1.12. With both exceptions activated, the TAG exception will take priority on simultaneous exceptions.
  [25:16] NCADDR — Non-Correctable Address: The value in this field is qualified by L2EDDNCSTATE.NCERR1, when that field is written to a 1, the address of the noncorrectable error is written to this register field. . Cleared upon writing a 1 to L2EDCMD.NCCLRLRU
  [9:0] CADDR — Correctable Address: The value in this field is qualified by L2EDDNCSTATE.CERR1, when that field is written to a 1, the address of the non-correctable error is written to this register field. . Cleared upon writing a 1 to L2EDCMD.NCCLRLRU
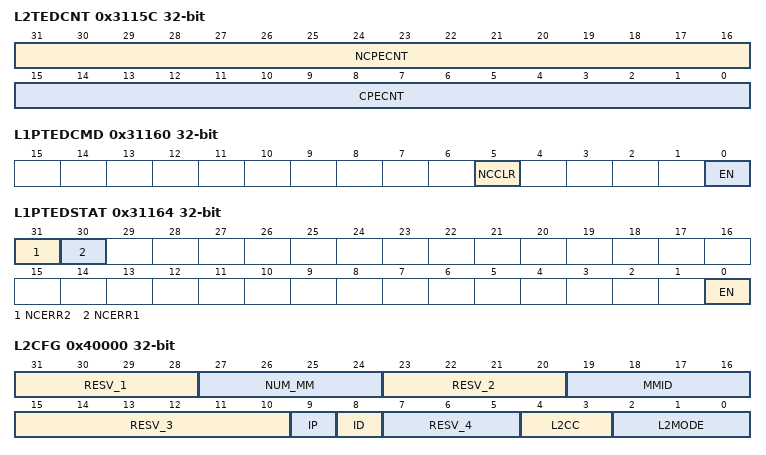
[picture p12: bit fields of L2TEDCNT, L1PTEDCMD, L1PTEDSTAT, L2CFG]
0x3115C L2TEDCNT ro — The L2 Error Detection Error Count Register.stores the error conts for correctable and non-correctable errors which occur in the L1D Data Memory, these counts are accumulated regardless of the exception mapping in the L1DEDCMD (0x0182_1108) interrupt enable bits. The counts contained in these registers are the accumulation of all L2 errors. This value saturates at an unsigned 0xFFFF.
  [31:16] NCPECNT — Non-correctable EDC error count. Shows the number of non-correctable errors which have occurred in the DMC memories since last reset. This counter is cleared by writing a zero value to the counter. CPECNT 15-0 0 Correctable EDC error count:
  [15:0] CPECNT — Correctable EDC error count: Shows the number of correctable errors which have occurred in the DMC memories since last reset. This counter is cleared by writing a zero value to the counter.
0x31160 L1PTEDCMD — This write only register provides control for enabling and disabling the Parity logic ofr the PMC. This register controls the parameters which are accumulated for the Data and Tag RAMs in the PMC. Enabling the Parity allows the counting of recoverable and non-recoverable errors as well as registering the requestor and the address and cache states for any Parity errors which are reported.
  [5] NCCLR wo — Non-Correctable Error Clear: Clears the non-correctable error count in the DMCEDPECNT register
  [0] EN wo — Enable Parity: Enables the Parity logic (parity_enable)
0x31164 L1PTEDSTAT — This read only regsister contains the current error. The register provides information on whether the error was correctable or non-correctable, the requestor, and what position the error was located.
  [31] NCERR2 ro — Non-Correctable Error: Indicates that there was a seconde non-correctable error, Also indicates the logged error is valid.
  [30] NCERR1 ro — Non-Correctable Error: Indicates the first error was noncorrectable.
  [0] EN ro — Enable: reflects the current state of the EN bit from L1PEDCMD
0x31168 L1PTEDADDR — The address error registers for correctable and non-correctable errors are identical in structure, the indication applies to the correctable and non-correctable errors, they are both covered in this section. The register provides a record of the address of the detected error and the access status or the cache.
  [26:16] NCADDR ro — Non-Correctable Address: The value in this field is qualified by L1PEDDNCSTATE.NCERR, when that field is written to a 1, the address of the non-correctable error is written to this register field. . Cleared upon writing a 1 to L1PEDCMD.NCCLRLR
0x3116C L1DTEDCNT — This read only register contains the counts of correctable and non-correctable errors which have occurred. To reset these counts write to the DMCEDCMD register in the appropriate bit.
  [31:16] NCPECNT ro — Non-correctable EDC error count. Shows the number of non-correctable errors which have occurred in the DMC memories since last reset. This counter is cleared by writing a zero value to the counter.
0x40000 L2CFG
  [31:28] RESV_1 — Always read as 0. Writes have no affect.
  [27:24] NUM_MM ro
  [23:20] RESV_2 — Always read as 0. Writes have no affect.
  [19:16] MMID ro
  [15:10] RESV_3 — Always read as 0. Writes have no affect.
  [9] IP
  [8] ID
  [7:5] RESV_4 — Always read as 0. Writes have no affect.
  [4:3] L2CC
  [2:0] L2MODE rw
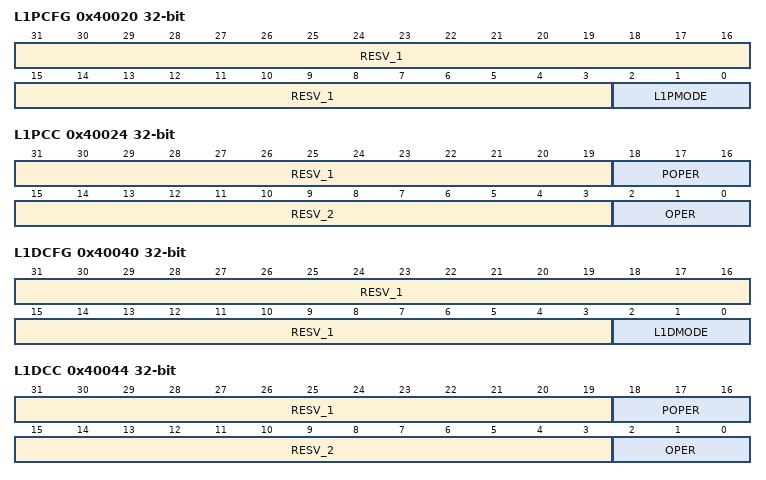
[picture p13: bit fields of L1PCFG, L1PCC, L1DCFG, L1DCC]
0x40020 L1PCFG
  [31:3] RESV_1 — Always read as 0. Writes have no affect.
  [2:0] L1PMODE rw
0x40024 L1PCC
  [31:19] RESV_1 — Always read as 0. Writes have no affect.
  [18:16] POPER ro
  [15:3] RESV_2 — Always read as 0. Writes have no affect.
  [2:0] OPER rw
0x40040 L1DCFG
  [31:3] RESV_1 — Always read as 0. Writes have no affect.
  [2:0] L1DMODE rw
0x40044 L1DCC
  fields as L1PCC
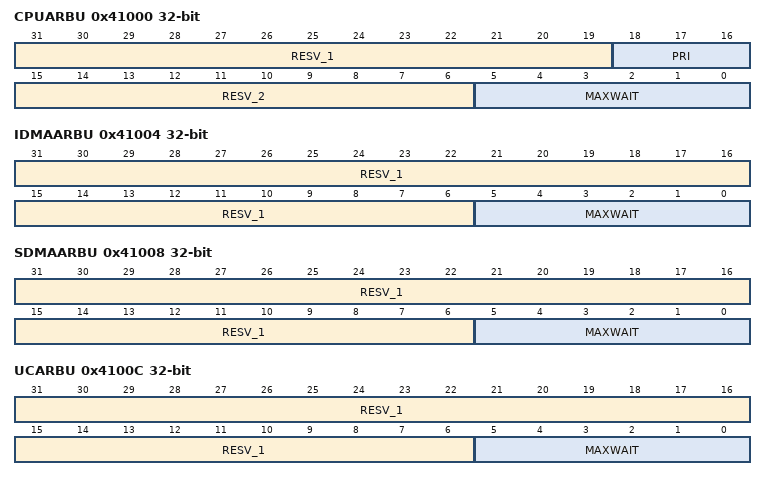
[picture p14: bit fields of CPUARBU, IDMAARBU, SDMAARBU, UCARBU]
0x41000 CPUARBU
  fields as CPUARBE
0x41004 IDMAARBU
  fields as IDMAARBE
0x41008 SDMAARBU
  fields as IDMAARBE
0x4100C UCARBU
  fields as IDMAARBE
0x41010 MDMAARBU
  [31:27] RESV_1 — Always read as 0. Writes have no affect.
  [26:24] UPRI rw — Elevated priority
  [23:19] RESV_2 — Always read as 0. Writes have no affect.
  [18:16] PRI rw — Default priority
  [15:0] RESV_3 — Always read as 0. Writes have no affect.
0x41040 CPUARBD
  fields as CPUARBE
0x41044 IDMAARBD
  fields as IDMAARBE
0x41048 SDMAARBD
  fields as IDMAARBE
0x4104C UCARBD
  fields as IDMAARBE
0x44000 L2WBAR wo
  [31:0] ADDR — Write only address register.
0x44004 L2WWC
  [31:16] RESV_1 — Always read as 0. Writes have no affect.
  [15:0] WC rw
0x44010 L2WIBAR wo
  [31:0] ADDR — Write only address register.
0x44014 L2WIWC
  fields as L2WWC
0x44018 L2IBAR wo
  [31:0] ADDR — Write only address register.
0x4401C L2IWC
  fields as L2WWC
0x44020 L1PIBAR wo
  [31:0] ADDR — Write only address register.
0x44024 L1PIWC
  fields as L2WWC
0x44030 L1DWIBAR wo
  [31:0] ADDR — Write only address register
0x44034 L1DWIWC
  fields as L2WWC
0x44040 L1DWBAR wo
  [31:0] ADDR — Write only address register
0x44044 L1DWWC
  fields as L2WWC
0x44048 L1DIBAR wo
  [31:0] ADDR — Write only address register
0x4404C L1DIWC
  fields as L2WWC
0x45000 L2WB rw
  [31:0] C
0x45004 L2WBINV rw
  [31:0] C
0x45008 L2INV rw
  [31:0] I
0x45028 L1PINV rw
  [31:0] I
0x45040 L1DWB rw
  [31:0] C
0x45044 L1DWBINV rw
  [31:0] C
0x45048 L1DINV rw
  [31:0] I
0x46004 L2EDSTAT — L2 EDC Status register
  [31:24] RESV1 — Always read as 0. Writes have no affect.
  [23:16] BITPOS ro — Bit position of Error
  [15:10] RESV2 — Always read as 0. Writes have no affect.
  [9:8] NERR ro — Non correctable Error
  [7] VERR ro — Victim EDC Error
  [6] DMAERR ro — DMA EDC Error
  [5] PERR ro — PMC Data EDC Error
  [4] DERR ro — DMC Data EDC Error
  [3] SUSP ro — EDC Suspend
  [2] DIS ro — EDC Disable
  [1] RESV3 — Always read as 0. Writes have no affect.
  [0] EN ro — EDC Enable
0x46008 L2EDCMD — L2 EDC Command register
  [31:8] RESV1 — Always read as 0. Writes have no affect.
  [7] VCLR wo — Victim EDC Error
  [6] DMACLR wo — DMA EDC Error
  [5] PCLR wo — PMC Data EDC Error
  [4] DCLR wo — DMC Data EDC Error
  [3] SUSP wo — EDC Suspend
  [2] DIS wo — EDC Disable
  [1] RESV3 — Always read as 0. Writes have no affect.
  [0] EN wo — EDC Enable
0x4600C L2EDADDR — L2 EDC error address
  [31:5] ADDR ro — L2 Error detection address
  [4:3] WAY ro — Addr way
  [2:1] RESV1 — Always read as 0. Writes have no affect.
  [0] RAM ro — Addr is sram
0x46018 L2EDCPEC — L2 EDC correctable error count
  [31:8] RESV1 — Always read as 0. Writes have no affect.
  [7:0] CNT ro — count
0x4601C L2EDCNEC — L2 EDC noncorrectable error count
  fields as L2EDCPEC
0x46020 MDMAERR
  fields as ECFGERR
0x46024 MDMAERRCLR
  fields as ECFGERRCLR
0x46030 L2EDCEN — L2 EDC enable register
  [31:5] RESV1 — Always read as 0. Writes have no affect.
  [4] SDMAEN wo — Enable edc on sdma reads to l2 sram
  [3] PL2SEN wo — Enable edc on pmc hits to l2 sram
  [2] DL2SEN wo — Enable edc on dmc hits to l2 sram
  [1] PL2CEN wo — Enable edc on pmc hits to l2 cache
  [0] DL2CEN wo — Enable edc on dmc hits to l2 cache
0x46404 L1PEDSTAT — L1P EDC Status register
  [31:7] RESV1 — Always read as 0. Writes have no affect.
  [6] DMAERR ro — DMA Error
  [5] PERR ro — Parity Error
  [4] RESV2 — Always read as 0. Writes have no affect.
  [3] SUSP ro — EDC Suspend
  [2] DIS ro — EDC Disable
  [1] RESV3 — Always read as 0. Writes have no affect.
  [0] EN ro — EDC Enable
0x46408 L1PEDCMD — L1P EDC Command register
  [31:7] RESV1 — Always read as 0. Writes have no affect.
  [6] DMACLR wo — Clear DMA Error
  [5] PCLR wo — Clear Parity Error
  [4] RESV2 — Always read as 0. Writes have no affect.
  [3] SUSP wo — EDC Suspend
  [2] DIS wo — EDC Disable
  [1] RESV3 — Always read as 0. Writes have no affect.
  [0] EN wo — EDC Enable
0x4640C L1PEDADDR — L1P EDC error address
  [31:5] ADDR ro — L1P Error detection address
  [4:1] RESV1 — Always read as 0. Writes have no affect.
  [0] RAM ro — Addr is sram
{0x48000+4i} MAR_{i} (i=0..255) — MAR register
  [31:4] RESV_1 — Always read as 0. Writes have no affect.
  [3] PFX ro — Hard coded to 0
  [2] PCX ro — Hard coded to 0
  [1] WTE ro — Hard coded to 0
  [0] PC ro — Hard coded to 1
0x4A000 L2MPFAR ro
  [31:0] ADDR
0x4A004 L2MPFSR
  [31:16] RESV_1 — Always read as 0. Writes have no affect.
  [15:9] FID ro — PrivID of faulting requestor
  [8] LOCAL ro — Fault due to local CPU access
  [7] NS ro — Fault due to non-secure code
  [6] RESV_2 — Always read as 0. Writes have no affect.
  [5] SR ro — Fault due to Supervisor Read
  [4] SW ro — Fault due to Supervisor Write
  [3] SX ro — Fault due to Supervisor Execute
  [2] UR ro — Fault due to User Read
  [1] UW ro — Fault due to User Write
  [0] UX ro — Fault due to User Execute
0x4A008 L2MPFCR
  fields as ICFGMPFCR
{0x4A200+4i} L2MPPA_{i} (i=0..31) — L2 Memory Protection Page Attribute register
  [31:16] RESV_1 — Always read as 0. Writes have no affect.
  [n+10] AID{n} rw (n=0..5) — Allow ID {n} to access page
  [9] AIDX rw — Allow IDs > 5 to access page
  [8] LOCAL rw — Allow CPU to access page
  [7] NS — Non-secure (Secure devices only)
  [6] EMU — Emulatable (Secure devices only)
  [5] SR rw — Supervisor Read Access
  [4] SW rw — Supervisor Write Access
  [3] SX rw — Supervisor Execute Access
  [2] UR rw — User Read Access
  [1] UW rw — User Write Access
  [0] UX rw — User Execute Access
0x4A400 L1PMPFAR ro
  [31:0] ADDR
0x4A404 L1PMPFSR
  fields as L2MPFSR
0x4A408 L1PMPFCR
  fields as ICFGMPFCR
{0x4A640+4i} L1PMPPA_{i} (i=0..15) — L1P Memory Protection Page Attribute register
  fields as L2MPPA_0
0x4AC00 L1DMPFAR ro
  [31:0] ADDR
0x4AC04 L1DMPFSR
  fields as L2MPFSR
0x4AC08 L1DMPFCR
  fields as ICFGMPFCR
{0x4AD00+4i} MPLK_{i} wo (i=0..3) — MPLK register
  [31:0] MPLK
0x4AD10 MPLKCMD
  [31:3] RESV_1 — Always read as 0. Writes have no affect.
  [2] KEYR wo
  [1] LOCK wo
  [0] UNLOCK wo
0x4AD14 MPLKSTAT
  [31:2] RESV_1 — Always read as 0. Writes have no affect.
  [1] NSL ro
  [0] LK ro
{0x4AE40+4i} L1DMPPA_{i} (i=0..15) — L1D Memory Protection Page Attribute register
  fields as L2MPPA_0
